VERSION " "

NS_ :

BS_:

BU_: Aquisition_Board1 Aquisition_Board2 Aquisition_Board3 Aquisition_Board4 Aquisition_Board5 Aquisition_Board6 Aquisition_Board7

BO_ 3221225472 VECTOR__INDEPENDENT_SIG_MSG: 0 Vector__XXX
 SG_ NewSignal_0002 : 0|8@1+ (1,0) [0|0] "" Vector__XXX
 SG_ NewSignal_0003 : 8|8@1+ (1,0) [0|0] "" Vector__XXX
 SG_ NewSignal_0004 : 16|8@1+ (1,0) [0|0] "" Vector__XXX
 SG_ NewSignal_0005 : 24|8@1+ (1,0) [0|0] "" Vector__XXX
 SG_ NewSignal_0006 : 32|8@1+ (1,0) [0|0] "" Vector__XXX
 SG_ NewSignal_0007 : 40|8@1+ (1,0) [0|0] "" Vector__XXX
 SG_ NewSignal_0008 : 48|8@1+ (1,0) [0|0] "" Vector__XXX
 SG_ NewSignal_0009 : 56|8@1+ (1,0) [0|0] "" Vector__XXX
 SG_ hydraulic_brake_pressure : 16|16@1+ (1,0) [0|0] "bits" Vector__XXX
 SG_ bots : 32|16@1+ (1,0) [0|0] "" Vector__XXX
 SG_ NewSignal_0010 : 32|8@1+ (1,0) [0|0] "" Vector__XXX

BO_ 1808 Pedal_Box: 8 Aquisition_Board1
 SG_ APPS1 : 0|16@1+ (0.1,0) [0|0] "bits" Vector__XXX
 SG_ APPS2 : 16|16@1+ (0.1,0) [0|0] "bits" Vector__XXX

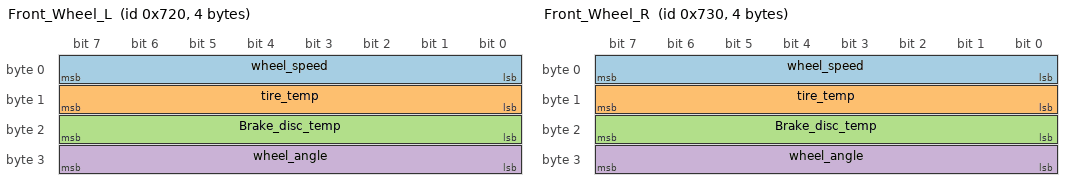
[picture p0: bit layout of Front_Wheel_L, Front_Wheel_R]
BO_ 1824 Front_Wheel_L: 4 Aquisition_Board2
 SG_ wheel_speed : 0|8@1+ (1,0) [0|0] "Km/h" Vector__XXX
 SG_ tire_temp : 8|8@1+ (1,0) [0|0] "º" Vector__XXX
 SG_ Brake_disc_temp : 16|8@1+ (1,0) [0|0] "º" Vector__XXX
 SG_ wheel_angle : 24|8@1+ (1,0) [0|0] "º" Vector__XXX

BO_ 1840 Front_Wheel_R: 4 Aquisition_Board3
 SG_ wheel_speed : 0|8@1+ (1,0) [0|0] "" Vector__XXX
 SG_ tire_temp : 8|8@1+ (1,0) [0|0] "" Vector__XXX
 SG_ Brake_disc_temp : 16|8@1+ (1,0) [0|0] "" Vector__XXX
 SG_ wheel_angle : 24|8@1+ (1,0) [0|0] "" Vector__XXX

BO_ 1856 Data_Box: 8 Aquisition_Board4
 SG_ suspension_level_left : 0|16@1+ (1,0) [0|0] "" Vector__XXX
 SG_ suspension_level_right : 16|16@1+ (1,0) [0|0] "" Vector__XXX

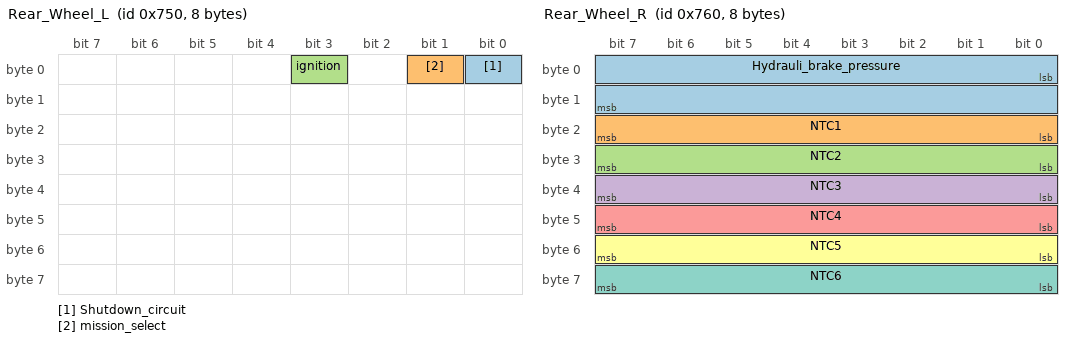
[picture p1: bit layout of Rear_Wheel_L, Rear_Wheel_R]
BO_ 1872 Rear_Wheel_L: 8 Aquisition_Board5
 SG_ Shutdown_circuit : 0|1@1+ (1,0) [0|0] "" Vector__XXX
 SG_ mission_select : 1|1@1+ (1,0) [0|0] "" Vector__XXX
 SG_ ignition : 3|1@1+ (1,0) [0|0] "" Vector__XXX

BO_ 1888 Rear_Wheel_R: 8 Aquisition_Board6
 SG_ Hydrauli_brake_pressure : 0|16@1+ (1,0) [0|0] "bar" Vector__XXX
 SG_ NTC1 : 16|8@1+ (1,0) [0|0] "º" Vector__XXX
 SG_ NTC2 : 24|8@1+ (1,0) [0|0] "º" Vector__XXX
 SG_ NTC3 : 32|8@1+ (1,0) [0|0] "º" Vector__XXX
 SG_ NTC4 : 40|8@1+ (1,0) [0|0] "º" Vector__XXX
 SG_ NTC5 : 48|8@1+ (1,0) [0|0] "º" Vector__XXX
 SG_ NTC6 : 56|8@1+ (1,0) [0|0] "º" Vector__XXX

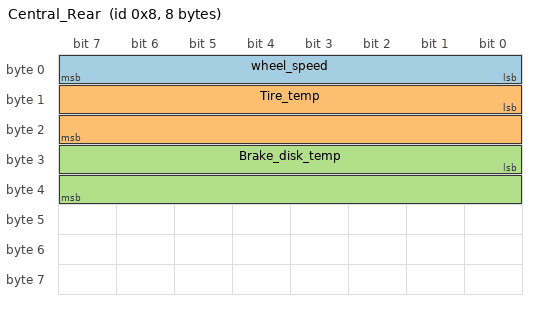
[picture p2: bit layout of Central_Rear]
BO_ 8 Central_Rear: 8 Aquisition_Board7
 SG_ wheel_speed : 0|8@1+ (1,0) [0|0] "" Vector__XXX
 SG_ Tire_temp : 8|16@1+ (10,0) [0|0] "" Vector__XXX
 SG_ Brake_disk_temp : 24|16@1+ (10,0) [0|0] "" Vector__XXX
